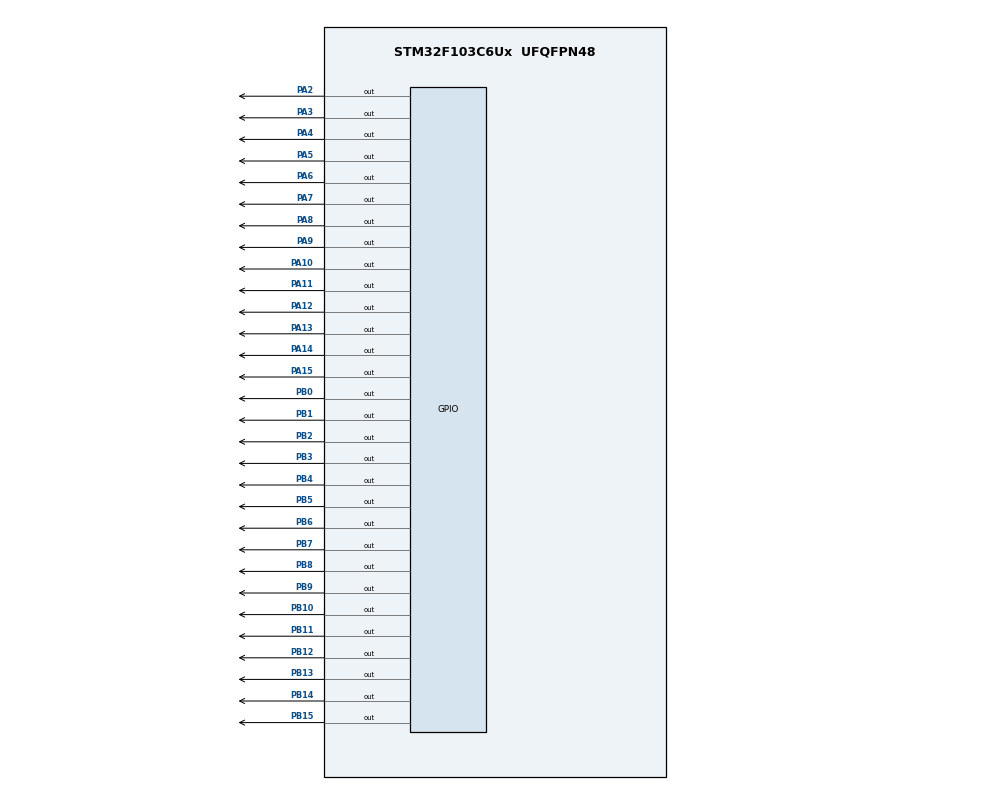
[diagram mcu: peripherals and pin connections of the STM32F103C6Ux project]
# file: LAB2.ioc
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Mcu.Family=STM32F1
Mcu.Name=STM32F103C6Ux
Mcu.Package=UFQFPN48
NVIC.PriorityGroup=NVIC_PRIORITYGROUP_4
NVIC.TIM2_IRQn=true\:0\:0\:false\:false\:true\:true\:true
PA10.Signal=GPIO_Output
PA11.Signal=GPIO_Output
PA12.Signal=GPIO_Output
PA13.Signal=GPIO_Output
PA14.Signal=GPIO_Output
PA15.Signal=GPIO_Output
PA2.Signal=GPIO_Output
PA3.Signal=GPIO_Output
PA4.Signal=GPIO_Output
PA5.Signal=GPIO_Output
PA6.Signal=GPIO_Output
PA7.Signal=GPIO_Output
PA8.Signal=GPIO_Output
PA9.Signal=GPIO_Output
PB0.Signal=GPIO_Output
PB1.Signal=GPIO_Output
PB10.Signal=GPIO_Output
PB11.Signal=GPIO_Output
PB12.Signal=GPIO_Output
PB13.Signal=GPIO_Output
PB14.Signal=GPIO_Output
PB15.Signal=GPIO_Output
PB2.Signal=GPIO_Output
PB3.Signal=GPIO_Output
PB4.Signal=GPIO_Output
PB5.Signal=GPIO_Output
PB6.Signal=GPIO_Output
PB7.Signal=GPIO_Output
PB8.Signal=GPIO_Output
PB9.Signal=GPIO_Output
ProjectManager.HeapSize=0x200
ProjectManager.StackSize=0x400
ProjectManager.TargetToolchain=STM32CubeIDE
RCC.APB1Freq_Value=8000000
RCC.APB2Freq_Value=8000000
TIM2.Period=9
TIM2.Prescaler=7999
VP_SYS_VS_ND.Mode=No_Debug
VP_TIM2_VS_ClockSourceINT.Mode=Internal
board=custom

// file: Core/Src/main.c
#include "main.h"
#include "led7_display.h"
#include "8x8matrix_display.h"

#define TIMER_CYCLE 		10

TIM_HandleTypeDef htim2;

void SystemClock_Config(void);
static void MX_GPIO_Init(void);
static void MX_TIM2_Init(void);

//timer for 2 dots
int timer0_counter = 0;
int timer0_flag = 0;
int min_flag = 0;

void setTimer0(int duration){
	timer0_counter = duration / TIMER_CYCLE;
	timer0_flag = 0;
}

void timer_run(){
	if(timer0_counter == 0)timer0_flag = 1;
	timer0_counter--;
}

int main(void)
{
  HAL_Init();
  SystemClock_Config();
  MX_GPIO_Init();
  MX_TIM2_Init();

  HAL_TIM_Base_Start_IT(&htim2);

  int hour = 15, min = 8, sec = 50;
  updateClockBuffer(min, sec);
  setTimer0(100);
  while (1)
  {
	  if(timer0_flag == 1){
	  	HAL_GPIO_TogglePin(GPIOA, GPIO_PIN_5);
	  	HAL_GPIO_TogglePin(GPIOA, GPIO_PIN_4);
	  	setTimer0(200);
		sec++;
	    if(sec >= 60){
	      sec = 0;
	      min++;
	    }if(min >= 60){
	      min = 0;
	      hour++;
	    }if(hour >= 24){
	      hour = 0;}
	    updateClockBuffer(min, sec);
	  }

	  display_matrix8x8_led();
		// Matrix 8x8

  }
  /* USER CODE END 3 */
}
void SystemClock_Config(void)
{
  RCC_OscInitTypeDef RCC_OscInitStruct = {0};
  RCC_ClkInitTypeDef RCC_ClkInitStruct = {0};

  /** Initializes the RCC Oscillators according to the specified parameters
  * in the RCC_OscInitTypeDef structure.
  */
  RCC_OscInitStruct.OscillatorType = RCC_OSCILLATORTYPE_HSI;
  RCC_OscInitStruct.HSIState = RCC_HSI_ON;
  RCC_OscInitStruct.HSICalibrationValue = RCC_HSICALIBRATION_DEFAULT;
  RCC_OscInitStruct.PLL.PLLState = RCC_PLL_NONE;
  if (HAL_RCC_OscConfig(&RCC_OscInitStruct) != HAL_OK)
  {
    Error_Handler();
  }
  /** Initializes the CPU, AHB and APB buses clocks
  */
  RCC_ClkInitStruct.ClockType = RCC_CLOCKTYPE_HCLK|RCC_CLOCKTYPE_SYSCLK
                              |RCC_CLOCKTYPE_PCLK1|RCC_CLOCKTYPE_PCLK2;
  RCC_ClkInitStruct.SYSCLKSource = RCC_SYSCLKSOURCE_HSI;
  RCC_ClkInitStruct.AHBCLKDivider = RCC_SYSCLK_DIV1;
  RCC_ClkInitStruct.APB1CLKDivider = RCC_HCLK_DIV1;
  RCC_ClkInitStruct.APB2CLKDivider = RCC_HCLK_DIV1;

  if (HAL_RCC_ClockConfig(&RCC_ClkInitStruct, FLASH_LATENCY_0) != HAL_OK)
  {
    Error_Handler();
  }
}

static void MX_TIM2_Init(void)
{

  TIM_ClockConfigTypeDef sClockSourceConfig = {0};
  TIM_MasterConfigTypeDef sMasterConfig = {0};

  htim2.Instance = TIM2;
  htim2.Init.Prescaler = 7999;
  htim2.Init.CounterMode = TIM_COUNTERMODE_UP;
  htim2.Init.Period = 9;
  htim2.Init.ClockDivision = TIM_CLOCKDIVISION_DIV1;
  htim2.Init.AutoReloadPreload = TIM_AUTORELOAD_PRELOAD_DISABLE;
  if (HAL_TIM_Base_Init(&htim2) != HAL_OK)
  {
    Error_Handler();
  }
  sClockSourceConfig.ClockSource = TIM_CLOCKSOURCE_INTERNAL;
  if (HAL_TIM_ConfigClockSource(&htim2, &sClockSourceConfig) != HAL_OK)
  {
    Error_Handler();
  }
  sMasterConfig.MasterOutputTrigger = TIM_TRGO_RESET;
  sMasterConfig.MasterSlaveMode = TIM_MASTERSLAVEMODE_DISABLE;
  if (HAL_TIMEx_MasterConfigSynchronization(&htim2, &sMasterConfig) != HAL_OK)
  {
    Error_Handler();
  }

}

static void MX_GPIO_Init(void)
{
  GPIO_InitTypeDef GPIO_InitStruct = {0};

  /* GPIO Ports Clock Enable */
  __HAL_RCC_GPIOA_CLK_ENABLE();
  __HAL_RCC_GPIOB_CLK_ENABLE();

  /*Configure GPIO pin Output Level */
  HAL_GPIO_WritePin(GPIOA, GPIO_PIN_8|GPIO_PIN_9|GPIO_PIN_10|GPIO_PIN_11|GPIO_PIN_12|GPIO_PIN_13
                              |GPIO_PIN_14|GPIO_PIN_15, SET);

  HAL_GPIO_WritePin(GPIOA, GPIO_PIN_2|GPIO_PIN_3|GPIO_PIN_4|GPIO_PIN_5
                          |GPIO_PIN_6|GPIO_PIN_7, GPIO_PIN_RESET);

  /*Configure GPIO pin Output Level */
  HAL_GPIO_WritePin(GPIOB, GPIO_PIN_0|GPIO_PIN_1|GPIO_PIN_2|GPIO_PIN_10
                          |GPIO_PIN_11|GPIO_PIN_12|GPIO_PIN_13|GPIO_PIN_14
                          |GPIO_PIN_15|GPIO_PIN_3|GPIO_PIN_4|GPIO_PIN_5
                          |GPIO_PIN_6|GPIO_PIN_7|GPIO_PIN_8|GPIO_PIN_9, GPIO_PIN_RESET);

  /*Configure GPIO pins : PA2 PA3 PA4 PA5
                           PA6 PA7 PA8 PA9
                           PA10 PA11 PA12 PA13
                           PA14 PA15 */
  GPIO_InitStruct.Pin = GPIO_PIN_2|GPIO_PIN_3|GPIO_PIN_4|GPIO_PIN_5
                          |GPIO_PIN_6|GPIO_PIN_7|GPIO_PIN_8|GPIO_PIN_9
                          |GPIO_PIN_10|GPIO_PIN_11|GPIO_PIN_12|GPIO_PIN_13
                          |GPIO_PIN_14|GPIO_PIN_15;
  GPIO_InitStruct.Mode = GPIO_MODE_OUTPUT_PP;
  GPIO_InitStruct.Pull = GPIO_NOPULL;
  GPIO_InitStruct.Speed = GPIO_SPEED_FREQ_LOW;
  HAL_GPIO_Init(GPIOA, &GPIO_InitStruct);

  /*Configure GPIO pins : PB0 PB1 PB2 PB10
                           PB11 PB12 PB13 PB14
                           PB15 PB3 PB4 PB5
                           PB6 PB7 PB8 PB9 */
  GPIO_InitStruct.Pin = GPIO_PIN_0|GPIO_PIN_1|GPIO_PIN_2|GPIO_PIN_10
                          |GPIO_PIN_11|GPIO_PIN_12|GPIO_PIN_13|GPIO_PIN_14
                          |GPIO_PIN_15|GPIO_PIN_3|GPIO_PIN_4|GPIO_PIN_5
                          |GPIO_PIN_6|GPIO_PIN_7|GPIO_PIN_8|GPIO_PIN_9;
  GPIO_InitStruct.Mode = GPIO_MODE_OUTPUT_PP;
  GPIO_InitStruct.Pull = GPIO_NOPULL;
  GPIO_InitStruct.Speed = GPIO_SPEED_FREQ_LOW;
  HAL_GPIO_Init(GPIOB, &GPIO_InitStruct);

}

/* USER CODE BEGIN 4 */

void HAL_TIM_PeriodElapsedCallback(TIM_HandleTypeDef *htim){
	timer_run();
	seven_segment_led_driver();
	//matrix8x8_led_driver();
}

/* USER CODE END 4 */

void Error_Handler(void)
{
  __disable_irq();
  while (1)
  {
  }
}

/************************ (C) COPYRIGHT STMicroelectronics *****END OF FILE****/
